AUTOSAR XML (schema 4-0-3)
package /MICROSAR/ComM_swc
  mode declaration group ComMMode: initial-mode=COMM_NO_COMMUNICATION
    mode COMM_NO_COMMUNICATION
    mode COMM_SILENT_COMMUNICATION
    mode COMM_FULL_COMMUNICATION
package /MICROSAR/ComM_swc/DataTypes
  4 x impl type, all with category=TYPE_REFERENCE, implementation-data-type=uint8:
    ComM_ModeType: compu {0=COMM_NO_COMMUNICATION, 1=COMM_SILENT_COMMUNICATION, 2=COMM_FULL_COMMUNICATION}
    ComM_InhibitionStatusType: range raw 0..255
    ComM_UserHandleType: range raw 0..255
    NetworkHandleType: range raw 0..255, type-emitter=ComM
package /MICROSAR/ComM_swc/Interfaces
  4 x client server interface, all with is-service=true, service-kind=COM-MANAGER:
    ComM_UserRequest
      4 x operation:
        RequestComMode: possible-error=[ComM_UserRequest/E_NOT_OK, E_MODE_LIMITATION]
          arg ComMode: type=ComM_ModeType, direction=IN
        GetCurrentComMode: possible-error=ComM_UserRequest/E_NOT_OK
          arg ComMode: type=ComM_ModeType, direction=OUT
        GetMaxComMode: possible-error=ComM_UserRequest/E_NOT_OK
          arg ComMode: type=ComM_ModeType, direction=OUT
        GetRequestedComMode: possible-error=ComM_UserRequest/E_NOT_OK
          arg ComMode: type=ComM_ModeType, direction=OUT
      error E_NOT_OK: error-code=1
      error E_MODE_LIMITATION: error-code=2
    ComM_ECUModeLimitation
      4 x operation, all with possible-error=ComM_ECUModeLimitation/E_NOT_OK:
        LimitECUToNoComMode
          arg Status: type=boolean, direction=IN
        ReadInhibitCounter
          arg CounterValue: type=uint16, direction=OUT
        ResetInhibitCounter
        SetECUGroupClassification
          arg Status: type=ComM_InhibitionStatusType, direction=IN
      error E_NOT_OK: error-code=1
    ComM_ChannelWakeUp
      operation PreventWakeUp: possible-error=ComM_ChannelWakeUp/E_NOT_OK
        arg Status: type=boolean, direction=IN
      operation GetInhibitionStatus: possible-error=ComM_ChannelWakeUp/E_NOT_OK
        arg Status: type=ComM_InhibitionStatusType, direction=OUT
      error E_NOT_OK: error-code=1
    ComM_ChannelLimitation
      operation LimitChannelToNoComMode: possible-error=ComM_ChannelLimitation/E_NOT_OK
        arg Status: type=boolean, direction=IN
      operation GetInhibitionStatus: possible-error=ComM_ChannelLimitation/E_NOT_OK
        arg Status: type=ComM_InhibitionStatusType, direction=OUT
      error E_NOT_OK: error-code=1
  mode switch interface ComM_CurrentMode: is-service=true, service-kind=COM-MANAGER
    mode group currentMode: type=ComMMode
package /MICROSAR/ComM_swc/ComponentTypes
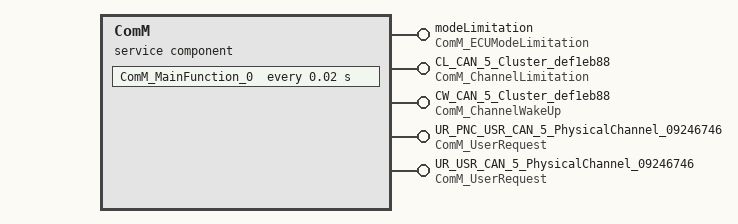
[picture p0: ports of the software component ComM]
  service sw component type ComM: category=SERVICE_COMPONENT
    5 x provide port:
      modeLimitation: provided-interface=ComM_ECUModeLimitation
      CL_CAN_5_Cluster_def1eb88: provided-interface=ComM_ChannelLimitation
      CW_CAN_5_Cluster_def1eb88: provided-interface=ComM_ChannelWakeUp
      UR_PNC_USR_CAN_5_PhysicalChannel_09246746: provided-interface=ComM_UserRequest
      UR_USR_CAN_5_PhysicalChannel_09246746: provided-interface=ComM_UserRequest
    behavior ComMInternalBehavior: handle-termination-and-restart=NO-SUPPORT, included-data-type-set=data-type=[ComM_ModeType, ComM_InhibitionStatusType, ComM_UserHandleType, NetworkHandleType]
      timing event Timer_ComM_MainFunction_0: start-on-event=ComM_MainFunction_0, period=0.02
      16 x operation invoked event:
        OpEventGetInhibitionStatus_GetInhibitionStatus_CL_CAN_5_Cluster_def1eb88: start-on-event=GetInhibitionStatus, operation=CL_CAN_5_Cluster_def1eb88.GetInhibitionStatus
        OpEventGetInhibitionStatus_GetInhibitionStatus_CW_CAN_5_Cluster_def1eb88: start-on-event=GetInhibitionStatus, operation=CW_CAN_5_Cluster_def1eb88.GetInhibitionStatus
        OpEventLimitECUToNoComMode_LimitECUToNoComMode_modeLimitation: start-on-event=LimitECUToNoComMode, operation=modeLimitation.LimitECUToNoComMode
        OpEventReadInhibitCounter_ReadInhibitCounter_modeLimitation: start-on-event=ReadInhibitCounter, operation=modeLimitation.ReadInhibitCounter
        OpEventResetInhibitCounter_ResetInhibitCounter_modeLimitation: start-on-event=ResetInhibitCounter, operation=modeLimitation.ResetInhibitCounter
        OpEventSetECUGroupClassification_SetECUGroupClassification_modeLimitation: start-on-event=SetECUGroupClassification, operation=modeLimitation.SetECUGroupClassification
        OpEventLimitChannelToNoComMode_LimitChannelToNoComMode_CL_CAN_5_Cluster_def1eb88: start-on-event=LimitChannelToNoComMode, operation=CL_CAN_5_Cluster_def1eb88.LimitChannelToNoComMode
        OpEventPreventWakeUp_PreventWakeUp_CW_CAN_5_Cluster_def1eb88: start-on-event=PreventWakeUp, operation=CW_CAN_5_Cluster_def1eb88.PreventWakeUp
        OpEventRequestComMode_RequestComMode_UR_PNC_USR_CAN_5_PhysicalChannel_09246746: start-on-event=RequestComMode, operation=UR_PNC_USR_CAN_5_PhysicalChannel_09246746.RequestComMode
        OpEventRequestComMode_RequestComMode_UR_USR_CAN_5_PhysicalChannel_09246746: start-on-event=RequestComMode, operation=UR_USR_CAN_5_PhysicalChannel_09246746.RequestComMode
        OpEventGetCurrentComMode_GetCurrentComMode_UR_PNC_USR_CAN_5_PhysicalChannel_09246746: start-on-event=GetCurrentComMode, operation=UR_PNC_USR_CAN_5_PhysicalChannel_09246746.GetCurrentComMode
        OpEventGetCurrentComMode_GetCurrentComMode_UR_USR_CAN_5_PhysicalChannel_09246746: start-on-event=GetCurrentComMode, operation=UR_USR_CAN_5_PhysicalChannel_09246746.GetCurrentComMode
        OpEventGetMaxComMode_GetMaxComMode_UR_PNC_USR_CAN_5_PhysicalChannel_09246746: start-on-event=GetMaxComMode, operation=UR_PNC_USR_CAN_5_PhysicalChannel_09246746.GetMaxComMode
        OpEventGetMaxComMode_GetMaxComMode_UR_USR_CAN_5_PhysicalChannel_09246746: start-on-event=GetMaxComMode, operation=UR_USR_CAN_5_PhysicalChannel_09246746.GetMaxComMode
        OpEventGetRequestedComMode_GetRequestedComMode_UR_PNC_USR_CAN_5_PhysicalChannel_09246746: start-on-event=GetRequestedComMode, operation=UR_PNC_USR_CAN_5_PhysicalChannel_09246746.GetRequestedComMode
        OpEventGetRequestedComMode_GetRequestedComMode_UR_USR_CAN_5_PhysicalChannel_09246746: start-on-event=GetRequestedComMode, operation=UR_USR_CAN_5_PhysicalChannel_09246746.GetRequestedComMode
      port-api-options:
        enable-take-address=true, indirect-api=false, port=modeLimitation
        {enable-take-address=true, indirect-api=false, port-defined-argument-value{value=0, value-type=NetworkHandleType}, port=CL_CAN_5_Cluster_def1eb88}
        {enable-take-address=true, indirect-api=false, port-defined-argument-value{value=0, value-type=NetworkHandleType}, port=CW_CAN_5_Cluster_def1eb88}
        {enable-take-address=true, indirect-api=false, port-defined-argument-value{value=1, value-type=ComM_UserHandleType}, port=UR_PNC_USR_CAN_5_PhysicalChannel_09246746}
        {enable-take-address=true, indirect-api=false, port-defined-argument-value{value=0, value-type=ComM_UserHandleType}, port=UR_USR_CAN_5_PhysicalChannel_09246746}
      12 x runnable, all with can-be-invoked-concurrently=true:
        ComM_MainFunction_0
        GetInhibitionStatus: symbol=ComM_GetInhibitionStatus
        LimitECUToNoComMode: symbol=ComM_LimitECUToNoComMode
        ReadInhibitCounter: symbol=ComM_ReadInhibitCounter
        ResetInhibitCounter: symbol=ComM_ResetInhibitCounter
        SetECUGroupClassification: symbol=ComM_SetECUGroupClassification
        LimitChannelToNoComMode: symbol=ComM_LimitChannelToNoComMode
        PreventWakeUp: symbol=ComM_PreventWakeUp
        RequestComMode: symbol=ComM_RequestComMode
        GetCurrentComMode: symbol=ComM_GetCurrentComMode
        GetMaxComMode: symbol=ComM_GetMaxComMode
        GetRequestedComMode: symbol=ComM_GetRequestedComMode
  swc implementation ComMImplementation: programming-language=C, behavior=ComMInternalBehavior
